VERSION ""

NS_ :

BS_:

BU_: BMSHV BMSLV ATC SW VCU SMU PCU LEM AMK EBS

BO_ 32 ResGO: 1 VCU
 SG_ go_signal : 0|1@1+ (1,0) [0|1] "" Vector__XXX

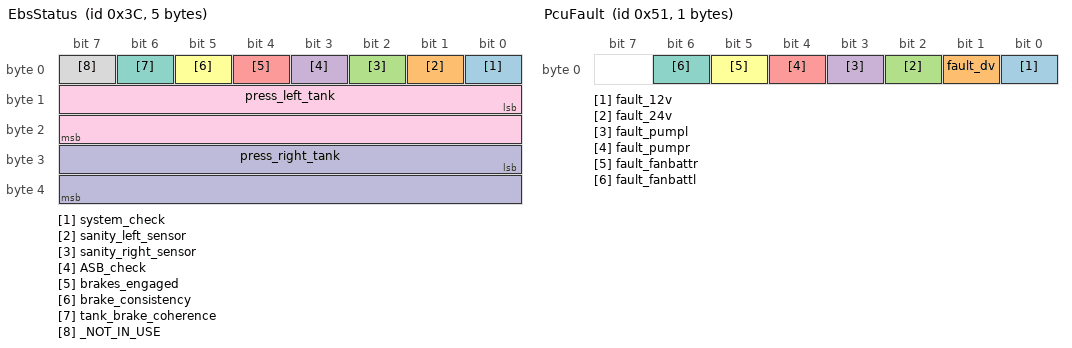
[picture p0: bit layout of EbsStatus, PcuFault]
BO_ 60 EbsStatus: 5 EBS
 SG_ system_check : 0|1@1+ (1,0) [0|1] "" Vector__XXX
 SG_ sanity_left_sensor : 1|1@1+ (1,0) [0|1] "" Vector__XXX
 SG_ sanity_right_sensor : 2|1@1+ (1,0) [0|1] "" Vector__XXX
 SG_ ASB_check : 3|1@1+ (1,0) [0|1] "" Vector__XXX
 SG_ brakes_engaged : 4|1@1+ (1,0) [0|1] "" Vector__XXX
 SG_ brake_consistency : 5|1@1+ (1,0) [0|1] "" Vector__XXX
 SG_ tank_brake_coherence : 6|1@1+ (1,0) [0|1] "" Vector__XXX
 SG_ _NOT_IN_USE : 7|1@1+ (1,0) [0|0] "" Vector__XXX
 SG_ press_left_tank : 8|16@1+ (0.001,0) [0|10] "Bar" Vector__XXX
 SG_ press_right_tank : 24|16@1+ (0.001,0) [0|10] "Bar" Vector__XXX

BO_ 65 Asms: 1 PCU
 SG_ Asms_sens : 0|1@1+ (1,0) [0|1] "High" Vector__XXX

BO_ 71 CarMission: 1 SW
 SG_ Mission : 0|3@1+ (1,0) [0|7] "" VCU

BO_ 81 PcuFault: 1 PCU
 SG_ fault_12v : 0|1@1+ (1,0) [0|1] "on" Vector__XXX
 SG_ fault_dv : 1|1@1+ (1,0) [0|1] "on" Vector__XXX
 SG_ fault_24v : 2|1@1+ (1,0) [0|1] "on" Vector__XXX
 SG_ fault_pumpl : 3|1@1+ (1,0) [0|1] "on" Vector__XXX
 SG_ fault_pumpr : 4|1@1+ (1,0) [0|1] "on" Vector__XXX
 SG_ fault_fanbattr : 5|1@1+ (1,0) [0|1] "on" Vector__XXX
 SG_ fault_fanbattl : 6|1@1+ (1,0) [0|1] "on" Vector__XXX

BO_ 82 Paddle: 1 SW
 SG_ regen : 0|8@1+ (1,0) [0|100] "%"  VCU

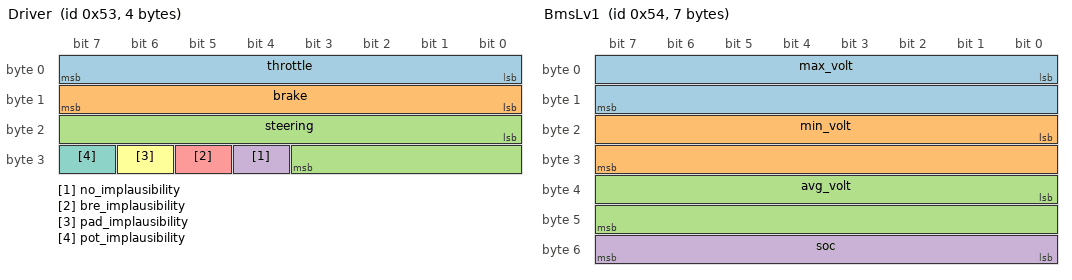
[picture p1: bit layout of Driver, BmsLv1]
BO_ 83 Driver: 4 ATC
 SG_ throttle : 0|8@1+ (1,0) [0|100] "%"  VCU,SW
 SG_ brake : 8|8@1+ (1,0) [0|100] "%"  VCU,SW
 SG_ steering : 16|12@1- (1,0) [-120|120] "deg"  VCU,SW
 SG_ no_implausibility : 28|1@1+ (1,0) [0|0] "" Vector__XXX
 SG_ bre_implausibility : 29|1@1+ (1,0) [0|0] "" Vector__XXX
 SG_ pad_implausibility : 30|1@1+ (1,0) [0|0] "" Vector__XXX
 SG_ pot_implausibility : 31|1@1+ (1,0) [0|0] "" Vector__XXX

BO_ 84 BmsLv1: 7 BMSHV
 SG_ max_volt : 0|16@1+ (0.1,0) [0|0] "mV"  VCU,SW
 SG_ min_volt : 16|16@1+ (0.1,0) [0|0] "mV"  VCU,SW
 SG_ avg_volt : 32|16@1+ (0.1,0) [0|0] "mV"  VCU,SW
 SG_ soc : 48|8@1+ (1,0) [0|100] "%"  VCU,SW

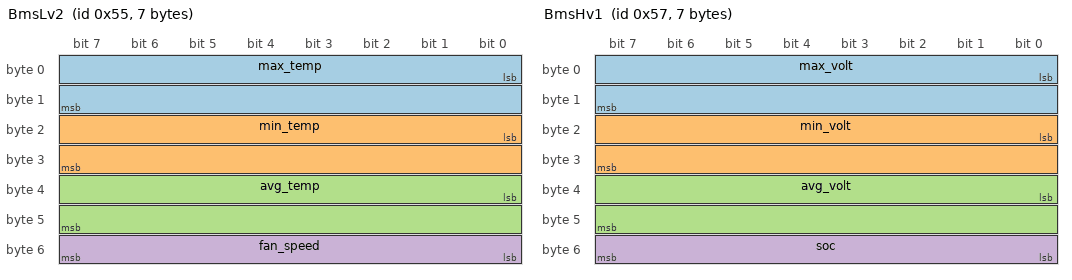
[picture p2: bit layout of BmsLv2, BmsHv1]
BO_ 85 BmsLv2: 7 BMSHV
 SG_ max_temp : 0|16@1+ (1,0) [0|0] "C"  VCU,SW
 SG_ min_temp : 16|16@1+ (1,0) [0|0] "C"  VCU,SW
 SG_ avg_temp : 32|16@1+ (1,0) [0|0] "C"  VCU,SW
 SG_ fan_speed : 48|8@1+ (1,0) [0|100] "%"  VCU,SW

BO_ 87 BmsHv1: 7 BMSHV
 SG_ max_volt : 0|16@1+ (0.1,0) [0|0] "mV"  VCU,SW
 SG_ min_volt : 16|16@1+ (0.1,0) [0|0] "mV"  VCU,SW
 SG_ avg_volt : 32|16@1+ (0.1,0) [0|0] "mV"  VCU,SW
 SG_ soc : 48|8@1+ (1,0) [0|100] "%"  VCU,SW

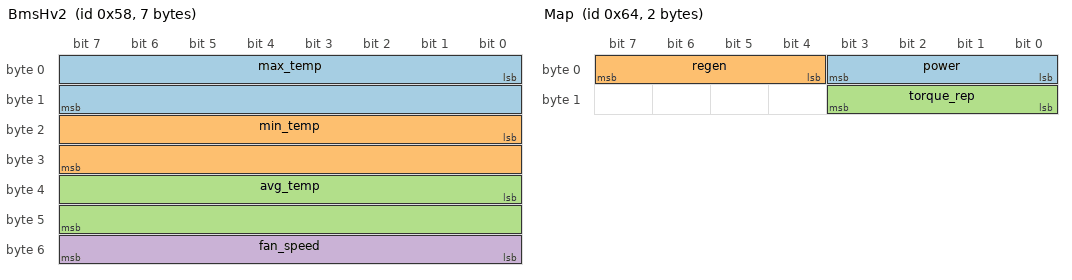
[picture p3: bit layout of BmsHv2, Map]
BO_ 88 BmsHv2: 7 BMSHV
 SG_ max_temp : 0|16@1+ (1,0) [0|0] "C"  VCU,SW
 SG_ min_temp : 16|16@1+ (1,0) [0|0] "C"  VCU,SW
 SG_ avg_temp : 32|16@1+ (1,0) [0|0] "C"  VCU,SW
 SG_ fan_speed : 48|8@1+ (1,0) [0|100] "%"  VCU,SW

BO_ 96 Imu1: 8 SMU
 SG_ acc_x : 0|32@1- (1,0) [0|0] "m/s^2"  VCU
 SG_ acc_y : 32|32@1- (1,0) [0|0] "m/s^2"  VCU

BO_ 97 Imu2: 8 SMU
 SG_ acc_z : 0|32@1- (1,0) [0|0] "m/s^2"  VCU
 SG_ omega_x : 32|32@1- (1,0) [0|0] "rad/s"  VCU

BO_ 98 Imu3: 8 SMU
 SG_ omega_y : 0|32@1- (1,0) [0|0] "rad/s"  VCU
 SG_ omega_z : 32|32@1- (1,0) [0|0] "rad/s"  VCU

BO_ 99 IMUCalib: 1 SMU
 SG_ start_imu_calibration : 0|1@1+ (1,0) [0|0] "" Vector__XXX

BO_ 100 Map: 2 SW
 SG_ power : 0|4@1+ (1,0) [1|12] "map"  VCU
 SG_ regen : 4|4@1+ (1,0) [1|12] "map"  VCU
 SG_ torque_rep : 8|4@1+ (1,0) [0|12] "map" Vector__XXX

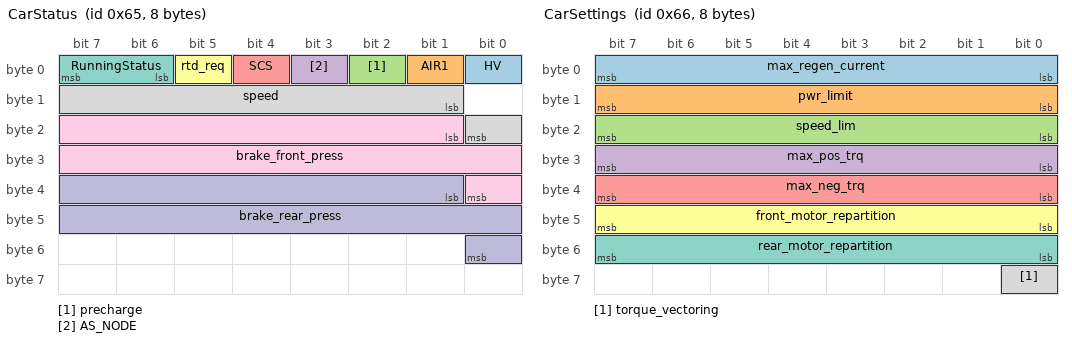
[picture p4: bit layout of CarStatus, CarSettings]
BO_ 101 CarStatus: 8 VCU
 SG_ HV : 0|1@1+ (1,0) [0|0] " Off/On" Vector__XXX
 SG_ AIR1 : 1|1@1+ (1,0) [0|0] " Closed/Open" Vector__XXX
 SG_ precharge : 2|1@1+ (1,0) [0|0] " Closed/Open" Vector__XXX
 SG_ AS_NODE : 3|1@1+ (1,0) [0|0] " Closed/Open" Vector__XXX
 SG_ SCS : 4|1@1+ (1,0) [0|0] " Closed/Open" Vector__XXX
 SG_ rtd_req : 5|1@1+ (1,0) [0|0] " Open/Closed" Vector__XXX
 SG_ RunningStatus : 6|2@1+ (1,0) [0|3] " Phase" Vector__XXX
 SG_ speed : 9|8@1+ (1,0) [0|0] " km/h" Vector__XXX
 SG_ brake_front_press : 17|16@1+ (0.001,0) [0|65] "Bar" Vector__XXX
 SG_ brake_rear_press : 33|16@1+ (0.001,0) [0|65] "Bar" Vector__XXX

BO_ 102 CarSettings: 8 VCU
 SG_ max_regen_current : 0|8@1+ (1,0) [0|150] "A" Vector__XXX
 SG_ pwr_limit : 8|8@1+ (1,0) [0|80] "kW" Vector__XXX
 SG_ speed_lim : 16|8@1+ (1,0) [0|0] "krpm" Vector__XXX
 SG_ max_pos_trq : 24|8@1+ (1,0) [0|0] "Nm" Vector__XXX
 SG_ max_neg_trq : 32|8@1- (1,0) [0|0] "Nm" Vector__XXX
 SG_ front_motor_repartition : 40|8@1+ (1,0) [0|0] "%" Vector__XXX
 SG_ rear_motor_repartition : 48|8@1+ (1,0) [0|0] "%" Vector__XXX
 SG_ torque_vectoring : 56|1@1+ (1,0) [0|1] "on" Vector__XXX

BO_ 104 CheckASBReq: 1 VCU
 SG_ req : 0|1@1+ (1,0) [0|1] "" Vector__XXX
 SG_ reqAck : 1|1@1+ (1,0) [0|1] "" Vector__XXX

BO_ 105 EbsBrakeReq: 1 VCU
 SG_ req : 0|1@1+ (1,0) [0|2] "" Vector__XXX

BO_ 106 ResStatus: 1 Vector__XXX
 SG_ data : 0|1@1+ (1,0) [0|2] "" Vector__XXX

BO_ 112 LapStart: 1 SW
 SG_ start : 0|8@1+ (1,0) [0|1] "start" Vector__XXX

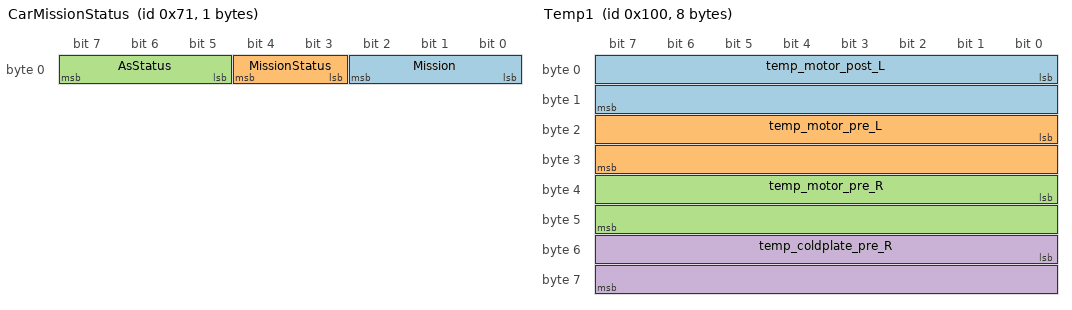
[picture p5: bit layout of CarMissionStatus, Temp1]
BO_ 113 CarMissionStatus: 1 VCU
 SG_ Mission : 0|3@1+ (1,0) [0|7] "" SW
 SG_ MissionStatus : 3|2@1+ (1,0) [0|2] "" SW
 SG_ AsStatus : 5|3@1+ (1,0) [0|7] "" SW

BO_ 256 Temp1: 8 SMU
SG_ temp_motor_post_L : 0|16@1+ (1,0) [0|0] "C"  VCU
 SG_ temp_motor_pre_L : 16|16@1+ (1,0) [0|0] "C"  VCU
 SG_ temp_motor_pre_R : 32|16@1+ (1,0) [0|0] "C"  VCU
 SG_ temp_coldplate_pre_R : 48|16@1+ (1,0) [0|0] "C"  VCU

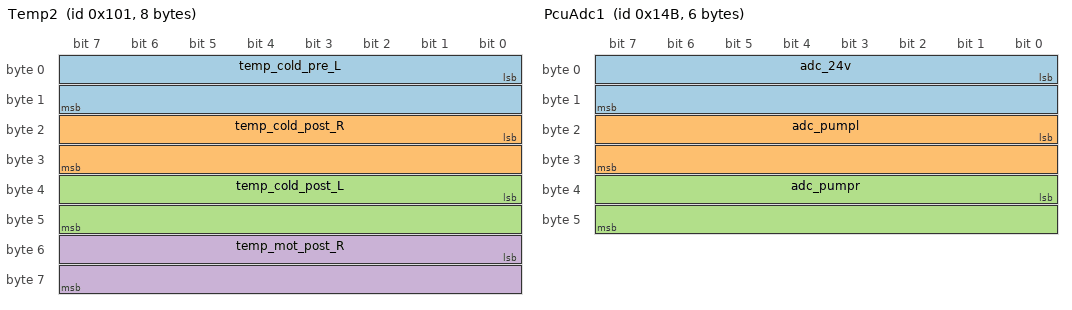
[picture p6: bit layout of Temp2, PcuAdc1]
BO_ 257 Temp2: 8 SMU
 SG_ temp_cold_pre_L : 0|16@1+ (1,0) [0|0] "C"  VCU
 SG_ temp_cold_post_R : 16|16@1+ (1,0) [0|0] "C"  VCU
 SG_ temp_cold_post_L : 32|16@1+ (1,0) [0|0] "C"  VCU
 SG_ temp_mot_post_R : 48|16@1+ (1,0) [0|0] "C"  VCU

BO_ 258 SuspRear: 3 SMU
 SG_ susp_rr : 0|12@1+ (0.1,0) [0|0] "mm"  VCU
 SG_ susp_rl : 12|12@1+ (0.1,0) [0|0] "mm"  VCU

BO_ 259 RESERVED2: 0 Vector__XXX

BO_ 260 SuspFront: 3 ATC
 SG_ susp_fr : 0|12@1+ (0.1,0) [0|0] "mm"  VCU
 SG_ susp_fl : 12|12@1+ (0.1,0) [0|0] "mm"  VCU

BO_ 261 TempFrontR: 3 ATC
 SG_ temp_mot_pot_FR : 0|10@1+ (1,0) [0|0] "C" Vector__XXX
 SG_ temp_mot_pre_FR : 10|10@1+ (1,0) [0|0] "C" Vector__XXX

BO_ 264 HydraulicPressure: 8 VCU
 SG_ PressFront : 0|32@1+ (1,0) [0|0] " Bar" Vector__XXX
 SG_ PressRear : 32|32@1+ (1,0) [0|0] " Bar" Vector__XXX

BO_ 288 InvVolt: 2 VCU
 SG_ car_voltage : 0|16@1+ (1,0) [0|600] "V"  VCU,SW,BMSHV

BO_ 304 Pcu: 7 VCU
 SG_ mode M : 0|2@1+ (1,0) [0|2] "" Vector__XXX
 SG_ pump_enable_left m0 : 8|1@1+ (1,0) [0|1] "on" Vector__XXX
 SG_ pump_speed_left m0 : 9|7@1+ (1,0) [0|100] "%" Vector__XXX
 SG_ pump_enable_right m0 : 16|1@1+ (1,0) [0|1] "on" Vector__XXX
 SG_ pump_speed_right m0 : 17|7@1+ (1,0) [0|100] "%" Vector__XXX
 SG_ fanrad_enable_left m0 : 24|1@1+ (1,0) [0|1] "on" Vector__XXX
 SG_ fanrad_speed_left m0 : 25|7@1+ (1,0) [0|100] "%" Vector__XXX
 SG_ fanrad_enable_right m0 : 32|1@1+ (1,0) [0|1] "on" Vector__XXX
 SG_ fanrad_speed_right m0 : 33|7@1+ (1,0) [0|100] "%" Vector__XXX
 SG_ fanbatt_enable_left m0 : 40|1@1+ (1,0) [0|1] "on" Vector__XXX
 SG_ fanbatt_speed_left m0 : 41|7@1+ (1,0) [0|100] "%" Vector__XXX
 SG_ fanbatt_enable_right m0 : 48|1@1+ (1,0) [0|1] "on" Vector__XXX
 SG_ fanbatt_speed_right m0 : 49|7@1+ (1,0) [0|100] "%" Vector__XXX
 SG_ rf m1 : 2|1@1+ (1,0) [0|1] "on" Vector__XXX
 SG_ enable_dv m2 : 2|1@1+ (1,0) [0|1] "on" Vector__XXX
 SG_ enable_embedded m2 : 3|1@1+ (1,0) [0|1] "on" Vector__XXX

BO_ 305 Calib: 1 SW
 SG_ position M : 0|8@1+ (1,0) [0|1] "high" ATC

BO_ 306 CalibAck: 1 ATC
 SG_ position M : 0|8@1+ (1,0) [0|1] "high" SW

BO_ 307 PcuSwControl: 1 SW
 SG_ pump : 0|1@1+ (1,0) [0|1] "" VCU
 SG_ fan : 1|1@1+ (1,0) [0|1] "" VCU

BO_ 308 PcuRfAck: 1 PCU
 SG_ rf_signalAck : 0|1@1+ (1,0) [0|1] "on" VCU

BO_ 310 EmbeddedAliveCheck: 0 VCU

BO_ 331 PcuAdc1: 6 PCU
 SG_ adc_24v : 0|16@1+ (0.001,0) [0|30] "A" Vector__XXX
 SG_ adc_pumpl : 16|16@1+ (0.001,0) [0|30] "A" Vector__XXX
 SG_ adc_pumpr : 32|16@1+ (0.001,0) [0|30] "A" Vector__XXX

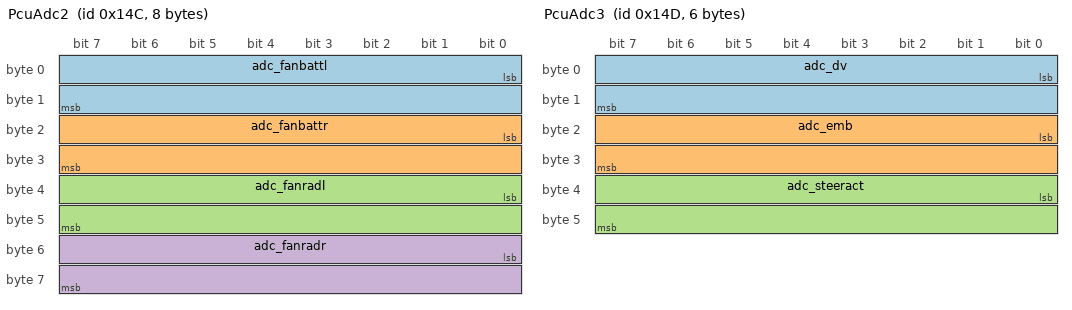
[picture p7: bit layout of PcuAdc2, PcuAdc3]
BO_ 332 PcuAdc2: 8 PCU
 SG_ adc_fanbattl : 0|16@1+ (0.001,0) [0|30] "A" Vector__XXX
 SG_ adc_fanbattr : 16|16@1+ (0.001,0) [0|30] "A" Vector__XXX
 SG_ adc_fanradl : 32|16@1+ (0.001,0) [0|30] "A" Vector__XXX
 SG_ adc_fanradr : 48|16@1+ (0.001,0) [0|30] "A" Vector__XXX

BO_ 333 PcuAdc3: 6 PCU
 SG_ adc_dv : 0|16@1+ (0.001,0) [0|30] "A" Vector__XXX
 SG_ adc_emb : 16|16@1+ (0.001,0) [0|30] "A" Vector__XXX
 SG_ adc_steeract : 32|16@1+ (0.001,0) [0|30] "A" Vector__XXX

BO_ 962 Lem: 8 LEM
 SG_ current : 7|32@0+ (1,-2147483648) [0|0] "mA" VCU,SW,BMSHV

CM_ SG_ 87 max_volt "Maximum cell voltage in mv";
CM_ SG_ 87 min_volt "Minimum cell voltage in mv";
CM_ SG_ 87 avg_volt "Average cell voltage in mv";
CM_ SG_ 87 soc "HV battery SOC in %";
CM_ SG_ 88 max_temp "Maximum cell temperature in celsius";
CM_ SG_ 88 min_temp "Minimum cell temperature in celsius";
CM_ SG_ 88 avg_temp "Average cell temperature in celsius";
CM_ SG_ 88 fan_speed "% of HV battery fan speed";
CM_ SG_ 84 volt1 "Cell 1 voltage in mv";
CM_ SG_ 84 volt2 "Cell 2 voltage in mv";
CM_ SG_ 84 volt3 "Cell 3 voltage in mv";
CM_ SG_ 84 volt4 "Cell 4 voltage in mv";
CM_ SG_ 85 volt5 "Cell 5 voltage in mv";
CM_ SG_ 85 volt6 "Cell 6 voltage in mv";
CM_ SG_ 85 temp1 "Temp linearized";
CM_ SG_ 85 temp2 "Temp linearized";
CM_ SG_ 962 current "Current seen from LEM on car side (PDB)";
CM_ SG_ 96 acc_x "Acceleration on x axis in m/s^2";
CM_ SG_ 96 acc_y "Acceleration on y axis in m/s^2";
CM_ SG_ 97 acc_z "Acceleration on z axis in m/s^2";
CM_ SG_ 97 omega_x "Angular speed on x axis in rad/s";
CM_ SG_ 98 omega_y "Angular speed on x axis in rad/s";
CM_ SG_ 98 omega_z "Angular speed on x axis in rad/s";
CM_ SG_ 258 susp_rr "RR suspension travel in mm";
CM_ SG_ 258 susp_rl "RL suspension travel in mm";
CM_ SG_ 288 car_voltage "Voltage seen from car side (inverter) in volts";
CM_ SG_ 83 throttle "% of throttle";
CM_ SG_ 83 brake "% of brake pedal";
CM_ SG_ 83 steering "Steering angle in milli radians";
CM_ SG_ 305 position "Set calibration of rest value (0) or 100% (1)";
CM_ SG_ 100 power "Map selected number";
CM_ SG_ 100 regen "Map selected for regen braking";
CM_ SG_ 100 torque_rep "Map selected for torque repeartition";
CM_ SG_ 82 regen "% of regen paddle travel";
CM_ SG_ 260 susp_fr "FR suspension travel in mm";
CM_ SG_ 260 susp_fl "FL suspension travel in mm";
CM_ BO_ 99 "RESERVER FOR IMU mask - DO NOT USE";
CM_ SG_ 102 max_regen_current "Maximum Regen Current";
CM_ SG_ 102 pwr_limit "Maximum power limit";
CM_ SG_ 102 speed_lim "Maximum Speed Limit";
CM_ SG_ 102 max_pos_trq "Maximum Positive Torque";
CM_ SG_ 102 max_neg_trq "Maximum Negative Torque";
CM_ SG_ 102 front_motor_repartition "Torque Repartition Front";
CM_ SG_ 102 rear_motor_repartition "Torque Repartition Rear";
CM_ SG_ 102 torque_vectoring "Torque Vectoring enabled";
CM_ BO_ 264 "Hydraulic Brakes Pressures";
CM_ SG_ 264 PressFront "0 means fault";
CM_ SG_ 264 PressRear "0 means fault";
CM_ BO_ 259 "RESERVER FOR SMU mask - DO NOT USE";

VAL_ 71 Mission 7 "dv_inspection" 6 "dv_ebs_test" 5 "dv_trackdrive" 4 "dv_autocross" 3 "dv_skidpad" 2 "dv_acceleration" 1 "manualy" 0 "none";
VAL_ 101 RunningStatus 3 "Running" 2 "Ts Ready" 1 "Precharge started" 0 "System off";
VAL_ 113 Mission 7 "dv_inspection" 6 "dv_ebs_test" 5 "dv_trackdrive" 4 "dv_autocross" 3 "dv_skidpad" 2 "dv_acceleration" 1 "manualy" 0 "none";
VAL_ 113 MissionStatus 2 "Mission_finished" 1 "Mission_running" 0 "Mission_not_running";
VAL_ 113 AsStatus 5 "finish" 4 "emergency_brake" 3 "driving" 2 "ready" 1 "off";
VAL_ 307 pump 1 "On" 0 "Off";
VAL_ 307 fan 1 "On" 0 "Off";

SIG_VALTYPE_ 96 acc_x : 1;
SIG_VALTYPE_ 96 acc_y : 1;
SIG_VALTYPE_ 97 acc_z : 1;
SIG_VALTYPE_ 97 omega_x : 1;
SIG_VALTYPE_ 98 omega_y : 1;
SIG_VALTYPE_ 98 omega_z : 1;

SG_MUL_VAL_ 304 rf mode 1-1;
SG_MUL_VAL_ 304 enable_dv mode 2-2;
SG_MUL_VAL_ 304 enable_embedded mode 2-2;
SG_MUL_VAL_ 304 pump_enable_left mode 0-0;
SG_MUL_VAL_ 304 pump_speed_left mode 0-0;
SG_MUL_VAL_ 304 pump_enable_right mode 0-0;
SG_MUL_VAL_ 304 pump_speed_right mode 0-0;
SG_MUL_VAL_ 304 fanrad_enable_left mode 0-0;
SG_MUL_VAL_ 304 fanrad_speed_left mode 0-0;
SG_MUL_VAL_ 304 fanrad_enable_right mode 0-0;
SG_MUL_VAL_ 304 fanrad_speed_right mode 0-0;
SG_MUL_VAL_ 304 fanbatt_enable_left mode 0-0;
SG_MUL_VAL_ 304 fanbatt_speed_left mode 0-0;
SG_MUL_VAL_ 304 fanbatt_enable_right mode 0-0;
SG_MUL_VAL_ 304 fanbatt_speed_right mode 0-0;
